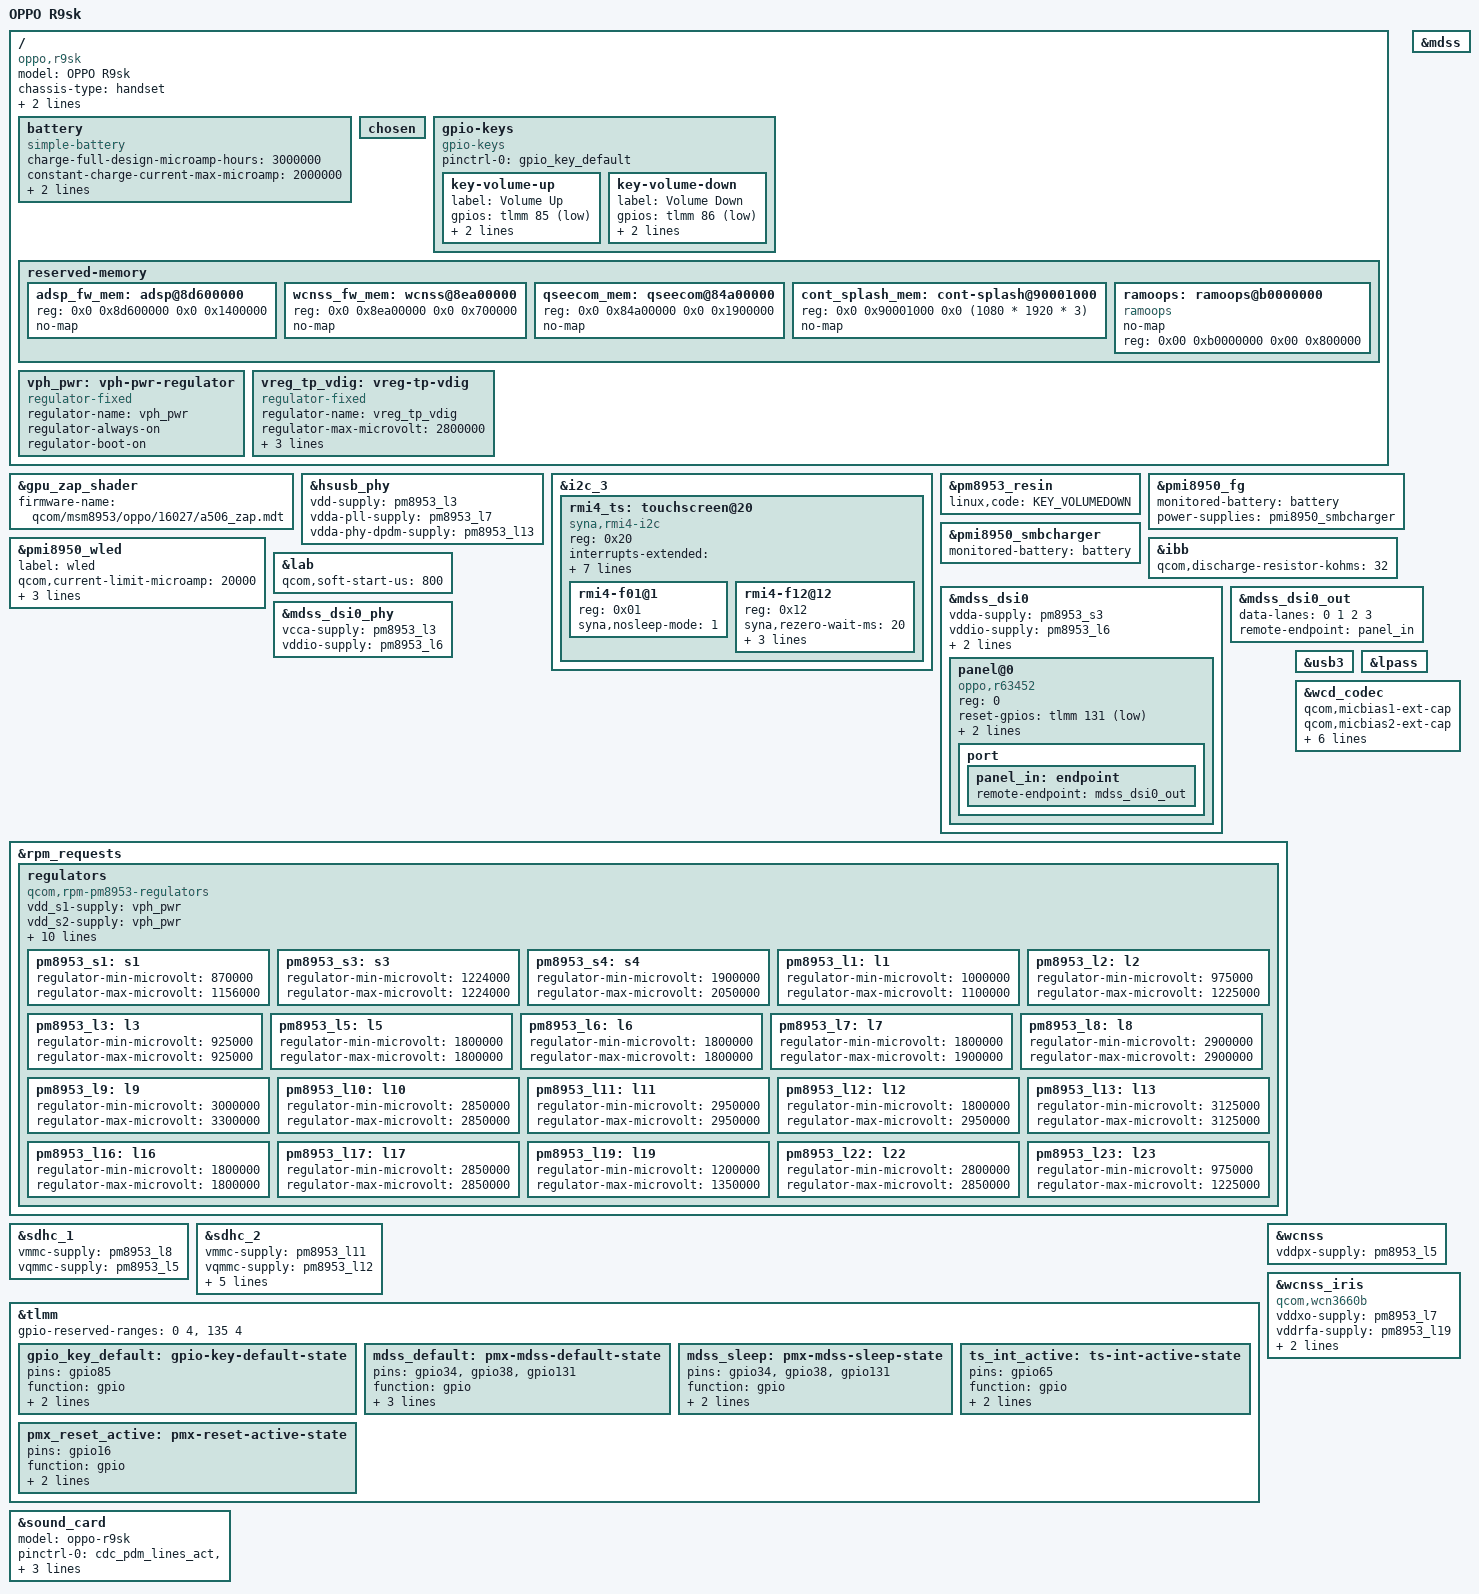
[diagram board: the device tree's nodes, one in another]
// SPDX-License-Identifier: BSD-3-Clause
/*
 * Copyright (c) 2026, Tikily
 * Copyright (c) 2026, ischenyu
 */
/dts-v1/;

#include "msm8953.dtsi"
#include "pm8953.dtsi"
#include "pmi8950.dtsi"

/delete-node/ &qseecom_mem;
/delete-node/ &wcnss_fw_mem;

/ {
	model = "OPPO R9sk";
	compatible = "oppo,r9sk", "qcom,msm8953";
	chassis-type = "handset";
	qcom,msm-id = <293 0>;
	qcom,board-id = <0x8 0x0 0x3e9b>;

	battery: battery {
		compatible = "simple-battery";

		charge-full-design-microamp-hours = <3000000>;
		constant-charge-current-max-microamp = <2000000>;
		voltage-min-design-microvolt = <3400000>;
		voltage-max-design-microvolt = <4350000>;
	};
	
	chosen {
		#address-cells = <2>;
		#size-cells = <2>;
		ranges;

		
	};

	gpio-keys {
		compatible = "gpio-keys";

		pinctrl-0 = <&gpio_key_default>;
		pinctrl-names = "default";

		key-volume-up {
			label = "Volume Up";
			gpios = <&tlmm 85 GPIO_ACTIVE_LOW>;
			linux,code = <KEY_VOLUMEUP>;
			debounce-interval = <15>;
		};
		key-volume-down {
			label = "Volume Down";
			gpios = <&tlmm 86 GPIO_ACTIVE_LOW>;
			linux,code = <KEY_VOLUMEDOWN>;
			debounce-interval = <15>;
		};
	};

	reserved-memory {
		/* this board's ADSP firmware needs a 20 MB region */
		adsp_fw_mem: adsp@8d600000 {
			reg = <0x0 0x8d600000 0x0 0x1400000>;
			no-map;
		};

		wcnss_fw_mem: wcnss@8ea00000 {
			reg = <0x0 0x8ea00000 0x0 0x700000>;
			no-map;
		};

		qseecom_mem: qseecom@84a00000 {
			reg = <0x0 0x84a00000 0x0 0x1900000>;
			no-map;
		};

		cont_splash_mem: cont-splash@90001000 {
			reg = <0x0 0x90001000 0x0 (1080 * 1920 * 3)>;
			no-map;
		};
		ramoops: ramoops@b0000000 {
		   compatible = "ramoops";
		   no-map;
		   reg = <0x00 0xb0000000 0x00 0x800000>;
		};
	};

	vph_pwr: vph-pwr-regulator {
		compatible = "regulator-fixed";
		regulator-name = "vph_pwr";
		regulator-always-on;
		regulator-boot-on;
	};

	vreg_tp_vdig: vreg-tp-vdig {
		compatible = "regulator-fixed";
		regulator-name = "vreg_tp_vdig";
		regulator-max-microvolt = <2800000>;
		regulator-min-microvolt = <2800000>;
		enable-active-high;
		gpio = <&tlmm 132 GPIO_ACTIVE_HIGH>;
	};
	
};

&gpu_zap_shader {
	firmware-name = "qcom/msm8953/oppo/16027/a506_zap.mdt";
};


&hsusb_phy {
	vdd-supply = <&pm8953_l3>;
	vdda-pll-supply = <&pm8953_l7>;
	vdda-phy-dpdm-supply = <&pm8953_l13>;

	status = "okay";
};

&i2c_3 {
	status = "okay";

	rmi4_ts: touchscreen@20 {
		reg = <0x20>;
		compatible = "syna,rmi4-i2c";
		interrupts-extended = <&tlmm 17 IRQ_TYPE_EDGE_FALLING>;

		#address-cells = <1>;
		#size-cells = <0>;

		vdd-supply = <&vreg_tp_vdig>;
		vio-supply = <&pm8953_l6>;

		pinctrl-names = "default", "sleep";
		pinctrl-0 = <&ts_int_active>;
		pinctrl-1 = <&pmx_reset_active>;

		syna,reset-delay-ms = <200>;
		syna,startup-delay-ms = <500>;


		rmi4-f01@1 {
			reg = <0x01>;
			syna,nosleep-mode = <1>;
		};

		rmi4-f12@12 {
			reg = <0x12>;
			syna,rezero-wait-ms = <20>;
			syna,sensor-type = <1>;
			touchscreen-x-mm = <68>;
			touchscreen-y-mm = <122>;
		};
	};

};

&pm8953_resin {
	linux,code = <KEY_VOLUMEDOWN>;
	status = "okay";
};

&pmi8950_fg {
	monitored-battery = <&battery>;
	power-supplies = <&pmi8950_smbcharger>;
	status = "okay";
};

&pmi8950_smbcharger {
	monitored-battery = <&battery>;
	status = "okay";
};

&pmi8950_wled {
	label = "wled";

	qcom,current-limit-microamp = <20000>;
	qcom,num-strings = <2>;
	qcom,ovp-millivolt = <29500>;
	qcom,external-pfet;

	status = "okay";
};

&ibb {
	qcom,discharge-resistor-kohms = <32>;
};

&lab {
	qcom,soft-start-us = <800>;
};

&mdss {
	status = "okay";
};

&mdss_dsi0 {

	vdda-supply = <&pm8953_s3>;
	vddio-supply = <&pm8953_l6>;


	pinctrl-0 = <&mdss_default &mdss_te_default>;
	pinctrl-1 = <&mdss_sleep &mdss_te_default>;
	pinctrl-names = "default", "sleep";

	status = "okay";

	panel@0 {
		compatible = "oppo,r63452";
		reg = <0>;



		reset-gpios = <&tlmm 131 GPIO_ACTIVE_LOW>;

		vsp-supply = <&lab>;
		vsn-supply = <&ibb>;

		port {
			panel_in: endpoint {
				remote-endpoint = <&mdss_dsi0_out>;
			};
		};
	};
};

&mdss_dsi0_out {
	data-lanes = <0 1 2 3>;
	remote-endpoint = <&panel_in>;
};

&mdss_dsi0_phy {
	vcca-supply = <&pm8953_l3>;
	vddio-supply = <&pm8953_l6>;

	status = "okay";
};

&rpm_requests {
	regulators {
		compatible = "qcom,rpm-pm8953-regulators";
		vdd_s1-supply = <&vph_pwr>;
		vdd_s2-supply = <&vph_pwr>;
		vdd_s3-supply = <&vph_pwr>;
		vdd_s4-supply = <&vph_pwr>;
		vdd_s5-supply = <&vph_pwr>;
		vdd_s6-supply = <&vph_pwr>;
		vdd_s7-supply = <&vph_pwr>;
		vdd_l1-supply = <&pm8953_s3>;
		vdd_l2_l3-supply = <&pm8953_s3>;
		vdd_l4_l5_l6_l7_l16_l19-supply = <&pm8953_s4>;
		vdd_l8_l11_l12_l13_l14_l15-supply = <&vph_pwr>;
		vdd_l9_l10_l17_l18_l22-supply = <&vph_pwr>;

		pm8953_s1: s1 {
			regulator-min-microvolt = <870000>;
			regulator-max-microvolt = <1156000>;
		};

		pm8953_s3: s3 {
			regulator-min-microvolt = <1224000>;
			regulator-max-microvolt = <1224000>;
		};

		pm8953_s4: s4 {
			regulator-min-microvolt = <1900000>;
			regulator-max-microvolt = <2050000>;
		};

		pm8953_l1: l1 {
			regulator-min-microvolt = <1000000>;
			regulator-max-microvolt = <1100000>;
		};

		pm8953_l2: l2 {
			regulator-min-microvolt = <975000>;
			regulator-max-microvolt = <1225000>;
		};

		pm8953_l3: l3 {
			regulator-min-microvolt = <925000>;
			regulator-max-microvolt = <925000>;
		};

		pm8953_l5: l5 {
			regulator-min-microvolt = <1800000>;
			regulator-max-microvolt = <1800000>;
		};

		pm8953_l6: l6 {
			regulator-min-microvolt = <1800000>;
			regulator-max-microvolt = <1800000>;
		};

		pm8953_l7: l7 {
			regulator-min-microvolt = <1800000>;
			regulator-max-microvolt = <1900000>;
		};

		pm8953_l8: l8 {
			regulator-min-microvolt = <2900000>;
			regulator-max-microvolt = <2900000>;
		};

		pm8953_l9: l9 {
			regulator-min-microvolt = <3000000>;
			regulator-max-microvolt = <3300000>;
		};

		pm8953_l10: l10 {
			regulator-min-microvolt = <2850000>;
			regulator-max-microvolt = <2850000>;
		};

		pm8953_l11: l11 {
			regulator-min-microvolt = <2950000>;
			regulator-max-microvolt = <2950000>;
		};

		pm8953_l12: l12 {
			regulator-min-microvolt = <1800000>;
			regulator-max-microvolt = <2950000>;
		};

		pm8953_l13: l13 {
			regulator-min-microvolt = <3125000>;
			regulator-max-microvolt = <3125000>;
		};

		pm8953_l16: l16 {
			regulator-min-microvolt = <1800000>;
			regulator-max-microvolt = <1800000>;
		};

		pm8953_l17: l17 {
			regulator-min-microvolt = <2850000>;
			regulator-max-microvolt = <2850000>;
		};

		pm8953_l19: l19 {
			regulator-min-microvolt = <1200000>;
			regulator-max-microvolt = <1350000>;
		};

		pm8953_l22: l22 {
			regulator-min-microvolt = <2800000>;
			regulator-max-microvolt = <2850000>;
		};

		pm8953_l23: l23 {
			regulator-min-microvolt = <975000>;
			regulator-max-microvolt = <1225000>;
		};

	};
};

&sdhc_1 {
	vmmc-supply = <&pm8953_l8>;
	vqmmc-supply = <&pm8953_l5>;

	status = "okay";
};

&sdhc_2 {
	vmmc-supply = <&pm8953_l11>;
	vqmmc-supply = <&pm8953_l12>;

	cd-gpios = <&tlmm 133 GPIO_ACTIVE_HIGH>;

	pinctrl-0 = <&sdc2_clk_on &sdc2_cmd_on &sdc2_data_on &sdc2_cd_on>;
	pinctrl-1 = <&sdc2_clk_off &sdc2_cmd_off &sdc2_data_off>;
	pinctrl-names = "default", "sleep";

	status = "okay";
};

&tlmm {
	gpio-reserved-ranges = <0 4>, <135 4>;

	gpio_key_default: gpio-key-default-state {
		pins = "gpio85";
		function = "gpio";
		drive-strength = <2>;
		bias-pull-up;
	};

	mdss_default: pmx-mdss-default-state {
		pins = "gpio34","gpio38","gpio131";
		function = "gpio";
		drive-strength = <8>;
		bias-disable;
		output-high;
	};

	mdss_sleep: pmx-mdss-sleep-state {
		pins = "gpio34","gpio38","gpio131";
		function = "gpio";
		drive-strength = <2>;
		bias-pull-down;
	};

	ts_int_active: ts-int-active-state {
		pins = "gpio65";
		function = "gpio";
		drive-strength = <8>;
		bias-pull-up;
	};

	pmx_reset_active: pmx-reset-active-state {
		pins = "gpio16";
		function = "gpio";
		drive-strength = <8>;
		bias-pull-up;
	};




};


&usb3 {
	status = "okay";
};


&lpass {
	status = "okay";
};

&sound_card {
	status = "okay";

	model = "oppo-r9sk";

	pinctrl-names = "default", "sleep";
	pinctrl-0 = <&cdc_pdm_lines_act &cdc_pdm_lines_2_act>;
	pinctrl-1 = <&cdc_pdm_lines_sus &cdc_pdm_lines_2_sus>;
};

&wcd_codec {
	status = "okay";

	qcom,micbias1-ext-cap;
	qcom,micbias2-ext-cap;
	qcom,hphl-jack-type-normally-open;

	qcom,mbhc-vthreshold-low = <75 150 237 450 500>;
	qcom,mbhc-vthreshold-high = <75 150 237 450 500>;

	vdd-cdc-io-supply = <&pm8953_l5>;
	vdd-cdc-tx-rx-cx-supply = <&pm8953_s4>;
	vdd-micbias-supply = <&pm8953_l13>;
};

&wcnss {
	vddpx-supply = <&pm8953_l5>;

	status = "okay";
};

&wcnss_iris {
	compatible = "qcom,wcn3660b";

	vddxo-supply = <&pm8953_l7>;
	vddrfa-supply = <&pm8953_l19>;
	vddpa-supply = <&pm8953_l9>;
	vdddig-supply = <&pm8953_l5>;
};
